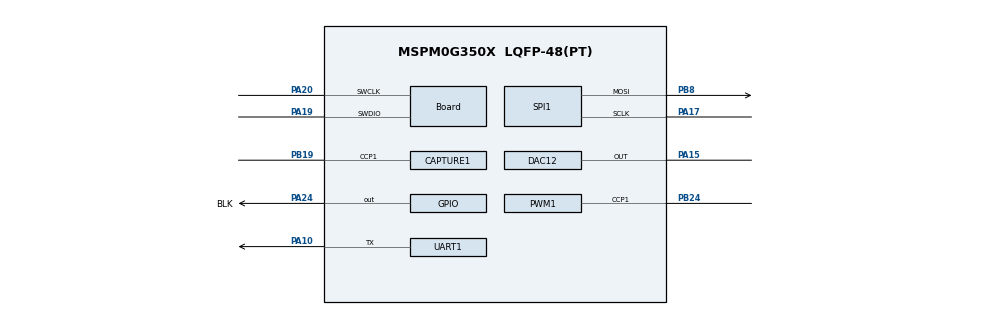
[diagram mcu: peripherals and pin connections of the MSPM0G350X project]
/**
 * @cliArgs --device "MSPM0G350X" --part "Default" --package "LQFP-48(PT)" --product "mspm0_sdk@2.03.00.08"
 * @versions {"tool":"1.21.1+3772"}
 */

/**
 * Import the modules used in this configuration.
 */
const ADC12    = scripting.addModule("/ti/driverlib/ADC12", {}, false);
const ADC121   = ADC12.addInstance();
const CAPTURE  = scripting.addModule("/ti/driverlib/CAPTURE", {}, false);
const CAPTURE1 = CAPTURE.addInstance();
const DAC12    = scripting.addModule("/ti/driverlib/DAC12");
const GPIO     = scripting.addModule("/ti/driverlib/GPIO", {}, false);
const GPIO1    = GPIO.addInstance();
const GPIO2    = GPIO.addInstance();
const GPIO3    = GPIO.addInstance();
const GPIO4    = GPIO.addInstance();
const PWM      = scripting.addModule("/ti/driverlib/PWM", {}, false);
const PWM1     = PWM.addInstance();
const SPI      = scripting.addModule("/ti/driverlib/SPI", {}, false);
const SPI1     = SPI.addInstance();
const SYSCTL   = scripting.addModule("/ti/driverlib/SYSCTL");
const UART     = scripting.addModule("/ti/driverlib/UART", {}, false);
const UART1    = UART.addInstance();

/**
 * Write custom configuration values to the imported modules.
 */
const gate8  = system.clockTree["MFPCLKGATE"];
gate8.enable = true;

ADC121.$name                             = "ADC12_0";
ADC121.configureDMA                      = true;
ADC121.sampCnt                           = 1;
ADC121.enabledDMATriggers                = ["DL_ADC12_DMA_MEM0_RESULT_LOADED"];
ADC121.repeatMode                        = true;
ADC121.adcMem0chansel                    = "DL_ADC12_INPUT_CHAN_6";
ADC121.adcMem0_name                      = "6";
ADC121.enabledInterrupts                 = ["DL_ADC12_INTERRUPT_DMA_DONE"];
ADC121.powerDownMode                     = "DL_ADC12_POWER_DOWN_MODE_MANUAL";
ADC121.sampClkDiv                        = "DL_ADC12_CLOCK_DIVIDE_32";
ADC121.sampleTime0                       = "100 us";
ADC121.peripheral.$assign                = "ADC0";
ADC121.peripheral.adcPin6.$assign        = "PB20";
ADC121.DMA_CHANNEL.$name                 = "DMA_CH0";
ADC121.DMA_CHANNEL.srcLength             = "HALF_WORD";
ADC121.DMA_CHANNEL.dstLength             = "HALF_WORD";
ADC121.DMA_CHANNEL.addressMode           = "f2b";
ADC121.DMA_CHANNEL.configureTransferSize = true;
ADC121.DMA_CHANNEL.transferSize          = 300;
ADC121.DMA_CHANNEL.transferMode          = "FULL_CH_REPEAT_SINGLE";
ADC121.adcPin6Config.$name               = "ti_driverlib_gpio_GPIOPinGeneric2";

const Board                       = scripting.addModule("/ti/driverlib/Board", {}, false);
Board.peripheral.$assign          = "DEBUGSS";
Board.peripheral.swclkPin.$assign = "PA20";
Board.peripheral.swdioPin.$assign = "PA19";

CAPTURE1.$name                      = "CAPTURE_0";
CAPTURE1.ccIndex                    = 1;
CAPTURE1.timerStartTimer            = true;
CAPTURE1.captMode                   = "EDGE_TIME_UP";
CAPTURE1.interrupts                 = ["CC1_UP"];
CAPTURE1.timerPeriod                = "65.535 ms";
CAPTURE1.timerClkPrescale           = 32;
CAPTURE1.peripheral.$assign         = "TIMG8";
CAPTURE1.peripheral.ccp1Pin.$assign = "PB19";
CAPTURE1.ccp1PinConfig.$name        = "ti_driverlib_gpio_GPIOPinGeneric4";

DAC12.dacOutputPinEn            = true;
DAC12.dacOutput12               = 2050;
DAC12.dacSampleTimerRate        = "16K";
DAC12.dacAmplifier              = "ON";
DAC12.peripheral.OutPin.$assign = "PA15";
DAC12.OutPinConfig.$name        = "ti_driverlib_gpio_GPIOPinGeneric6";

GPIO1.$name                              = "GPIO_LCD";
GPIO1.associatedPins.create(4);
GPIO1.associatedPins[0].$name            = "CS";
GPIO1.associatedPins[0].initialValue     = "SET";
GPIO1.associatedPins[0].assignedPort     = "PORTB";
GPIO1.associatedPins[0].assignedPin      = "9";
GPIO1.associatedPins[0].internalResistor = "PULL_UP";
GPIO1.associatedPins[0].ioStructure      = "SD";
GPIO1.associatedPins[1].$name            = "RES";
GPIO1.associatedPins[1].initialValue     = "SET";
GPIO1.associatedPins[1].internalResistor = "PULL_UP";
GPIO1.associatedPins[1].ioStructure      = "SD";
GPIO1.associatedPins[1].assignedPort     = "PORTA";
GPIO1.associatedPins[1].assignedPin      = "21";
GPIO1.associatedPins[2].$name            = "DC";
GPIO1.associatedPins[2].initialValue     = "SET";
GPIO1.associatedPins[2].internalResistor = "PULL_UP";
GPIO1.associatedPins[2].assignedPort     = "PORTA";
GPIO1.associatedPins[2].assignedPin      = "22";
GPIO1.associatedPins[3].$name            = "BLK";
GPIO1.associatedPins[3].initialValue     = "SET";
GPIO1.associatedPins[3].assignedPort     = "PORTA";
GPIO1.associatedPins[3].assignedPin      = "24";
GPIO1.associatedPins[3].internalResistor = "PULL_UP";
GPIO1.associatedPins[3].ioStructure      = "SD";
GPIO1.associatedPins[3].pin.$assign      = "PA24";

GPIO2.$name                               = "GPIO_EC11";
GPIO2.associatedPins.create(3);
GPIO2.associatedPins[0].$name             = "KEYA";
GPIO2.associatedPins[0].assignedPort      = "PORTA";
GPIO2.associatedPins[0].assignedPin       = "26";
GPIO2.associatedPins[0].initialValue      = "SET";
GPIO2.associatedPins[0].direction         = "INPUT";
GPIO2.associatedPins[0].internalResistor  = "PULL_UP";
GPIO2.associatedPins[0].interruptEn       = true;
GPIO2.associatedPins[0].interruptPriority = "1";
GPIO2.associatedPins[0].polarity          = "RISE_FALL";
GPIO2.associatedPins[1].$name             = "KEYB";
GPIO2.associatedPins[1].assignedPort      = "PORTA";
GPIO2.associatedPins[1].assignedPin       = "25";
GPIO2.associatedPins[1].direction         = "INPUT";
GPIO2.associatedPins[1].internalResistor  = "PULL_UP";
GPIO2.associatedPins[2].$name             = "KEYD";
GPIO2.associatedPins[2].initialValue      = "SET";
GPIO2.associatedPins[2].internalResistor  = "PULL_UP";
GPIO2.associatedPins[2].assignedPort      = "PORTA";
GPIO2.associatedPins[2].assignedPin       = "27";
GPIO2.associatedPins[2].direction         = "INPUT";

GPIO3.$name                               = "GPIO_KEY";
GPIO3.associatedPins.create(3);
GPIO3.associatedPins[0].$name             = "PIN_1";
GPIO3.associatedPins[0].direction         = "INPUT";
GPIO3.associatedPins[0].internalResistor  = "PULL_UP";
GPIO3.associatedPins[0].assignedPort      = "PORTA";
GPIO3.associatedPins[0].assignedPin       = "12";
GPIO3.associatedPins[0].interruptEn       = true;
GPIO3.associatedPins[0].interruptPriority = "1";
GPIO3.associatedPins[0].polarity          = "FALL";
GPIO3.associatedPins[1].$name             = "PIN_2";
GPIO3.associatedPins[1].direction         = "INPUT";
GPIO3.associatedPins[1].assignedPort      = "PORTA";
GPIO3.associatedPins[1].assignedPin       = "13";
GPIO3.associatedPins[1].internalResistor  = "PULL_UP";
GPIO3.associatedPins[1].interruptEn       = true;
GPIO3.associatedPins[1].interruptPriority = "1";
GPIO3.associatedPins[1].polarity          = "FALL";
GPIO3.associatedPins[2].$name             = "PIN_3";
GPIO3.associatedPins[2].direction         = "INPUT";
GPIO3.associatedPins[2].assignedPort      = "PORTA";
GPIO3.associatedPins[2].assignedPin       = "16";
GPIO3.associatedPins[2].internalResistor  = "PULL_UP";
GPIO3.associatedPins[2].interruptEn       = true;
GPIO3.associatedPins[2].interruptPriority = "1";
GPIO3.associatedPins[2].polarity          = "FALL";

GPIO4.$name                              = "GPIO_LED";
GPIO4.associatedPins.create(2);
GPIO4.associatedPins[0].$name            = "NUM1";
GPIO4.associatedPins[0].initialValue     = "SET";
GPIO4.associatedPins[0].internalResistor = "PULL_UP";
GPIO4.associatedPins[0].assignedPort     = "PORTA";
GPIO4.associatedPins[0].assignedPin      = "28";
GPIO4.associatedPins[1].$name            = "NUM2";
GPIO4.associatedPins[1].initialValue     = "SET";
GPIO4.associatedPins[1].internalResistor = "PULL_UP";
GPIO4.associatedPins[1].assignedPort     = "PORTA";
GPIO4.associatedPins[1].assignedPin      = "31";

PWM1.$name                      = "PWM_0";
PWM1.ccIndex                    = [1];
PWM1.timerStartTimer            = true;
PWM1.timerCount                 = 32000;
PWM1.peripheral.$assign         = "TIMG12";
PWM1.peripheral.ccp1Pin.$assign = "PB24";
PWM1.ccp1PinConfig.$name        = "ti_driverlib_gpio_GPIOPinGeneric5";
PWM1.PWM_CHANNEL_1.$name        = "ti_driverlib_pwm_PWMTimerCC0";
PWM1.PWM_CHANNEL_1.invert       = true;
PWM1.PWM_CHANNEL_1.dutyCycle    = 50;

SPI1.frameFormat                        = "MOTO3";
SPI1.$name                              = "SPI_LCD";
SPI1.targetBitRate                      = 1600000;
SPI1.direction                          = "PICO";
SPI1.phase                              = "1";
SPI1.peripheral.$assign                 = "SPI1";
SPI1.peripheral.sclkPin.$assign         = "PA17";
SPI1.peripheral.mosiPin.$assign         = "PB8";
SPI1.sclkPinConfig.direction            = scripting.forceWrite("OUTPUT");
SPI1.sclkPinConfig.onlyInternalResistor = scripting.forceWrite(false);
SPI1.sclkPinConfig.passedPeripheralType = scripting.forceWrite("Digital");
SPI1.sclkPinConfig.$name                = "ti_driverlib_gpio_GPIOPinGeneric0";
SPI1.mosiPinConfig.direction            = scripting.forceWrite("OUTPUT");
SPI1.mosiPinConfig.hideOutputInversion  = scripting.forceWrite(false);
SPI1.mosiPinConfig.onlyInternalResistor = scripting.forceWrite(false);
SPI1.mosiPinConfig.passedPeripheralType = scripting.forceWrite("Digital");
SPI1.mosiPinConfig.$name                = "ti_driverlib_gpio_GPIOPinGeneric1";

SYSCTL.forceDefaultClkConfig = true;
SYSCTL.clockTreeEn           = true;
SYSCTL.validateClkStatus     = true;

UART1.$name                    = "UART_0";
UART1.interruptPriority        = "1";
UART1.direction                = "TX";
UART1.peripheral.txPin.$assign = "PA10";
UART1.txPinConfig.$name        = "ti_driverlib_gpio_GPIOPinGeneric3";

const ProjectConfig              = scripting.addModule("/ti/project_config/ProjectConfig", {}, false);
ProjectConfig.migrationCondition = true;

/**
 * Pinmux solution for unlocked pins/peripherals. This ensures that minor changes to the automatic solver in a future
 * version of the tool will not impact the pinmux you originally saw.  These lines can be completely deleted in order to
 * re-solve from scratch.
 */
ADC121.DMA_CHANNEL.peripheral.$suggestSolution = "DMA_CH0";
DAC12.peripheral.$suggestSolution              = "DAC0";
GPIO1.associatedPins[0].pin.$suggestSolution   = "PB9";
GPIO1.associatedPins[1].pin.$suggestSolution   = "PA21";
GPIO1.associatedPins[2].pin.$suggestSolution   = "PA22";
GPIO2.associatedPins[0].pin.$suggestSolution   = "PA26";
GPIO2.associatedPins[1].pin.$suggestSolution   = "PA25";
GPIO2.associatedPins[2].pin.$suggestSolution   = "PA27";
GPIO3.associatedPins[0].pin.$suggestSolution   = "PA12";
GPIO3.associatedPins[1].pin.$suggestSolution   = "PA13";
GPIO3.associatedPins[2].pin.$suggestSolution   = "PA16";
GPIO4.associatedPins[0].pin.$suggestSolution   = "PA28";
GPIO4.associatedPins[1].pin.$suggestSolution   = "PA31";
UART1.peripheral.$suggestSolution              = "UART0";
